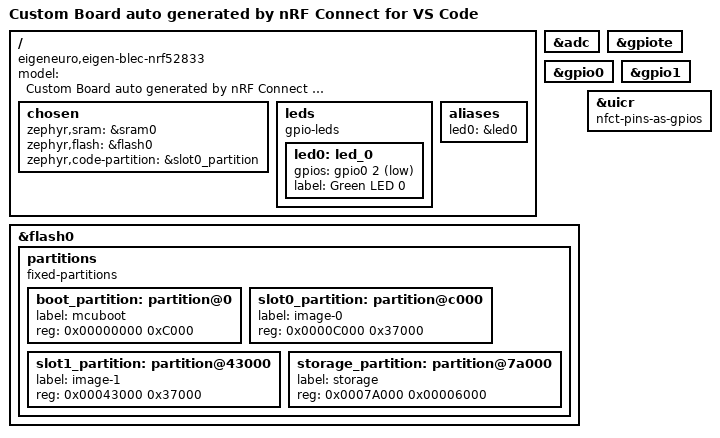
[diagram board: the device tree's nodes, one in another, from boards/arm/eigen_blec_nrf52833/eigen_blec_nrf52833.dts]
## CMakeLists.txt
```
cmake_minimum_required(VERSION 3.20.0)

list(APPEND BOARD_ROOT ${CMAKE_CURRENT_LIST_DIR})

find_package(Zephyr REQUIRED HINTS $ENV{ZEPHYR_BASE})
project(EigenBLEC)

FILE(GLOB app_sources src/*.c src/inc/*.h drivers/*.c drivers/*.h)
target_sources(app PRIVATE ${app_sources} src/main.c)

# Relax warnings-as-errors for unused variables in app sources.
target_compile_options(app PRIVATE -Wno-error=unused-variable)

# ---- Hard guard (file-based): strip UICR after zephyr.hex exists ----
find_package(Python3 REQUIRED COMPONENTS Interpreter)

set(ZEPHYR_HEX      ${PROJECT_BINARY_DIR}/zephyr/zephyr.hex)
set(ZEPHYR_HEX_NOUICR ${PROJECT_BINARY_DIR}/zephyr/zephyr.hex.nouicr)
set(STRIP_SCRIPT    ${CMAKE_CURRENT_LIST_DIR}/scripts/strip_uicr_hex.py)

add_custom_command(
  OUTPUT ${ZEPHYR_HEX_NOUICR}
  COMMAND ${CMAKE_COMMAND} -E echo "Stripping UICR from ${ZEPHYR_HEX}"
  COMMAND ${Python3_EXECUTABLE} ${STRIP_SCRIPT} ${ZEPHYR_HEX} ${ZEPHYR_HEX_NOUICR}
  COMMAND ${CMAKE_COMMAND} -E copy ${ZEPHYR_HEX_NOUICR} ${ZEPHYR_HEX}
  DEPENDS ${ZEPHYR_HEX} ${STRIP_SCRIPT}
  VERBATIM
)

add_custom_target(strip_uicr ALL DEPENDS ${ZEPHYR_HEX_NOUICR})

# Ensure west flash (ninja flash) runs strip_uicr first
if(TARGET flash)
  add_dependencies(flash strip_uicr)
endif()

# Some Zephyr versions use runners/flash targets with different names
if(TARGET runners)
  add_dependencies(runners strip_uicr)
endif()
```

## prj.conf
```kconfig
# 先把所有日志/控制台关掉（很多卡死发生在串口/console init）
CONFIG_LOG=y
CONFIG_CONSOLE=n
CONFIG_UART_CONSOLE=n
CONFIG_PRINTK=y
CONFIG_SERIAL=n
CONFIG_USE_SEGGER_RTT=y
CONFIG_SHELL_BACKEND_RTT=y

# printk/printf 支持 float
CONFIG_CBPRINTF_NANO=n
CONFIG_CBPRINTF_FP_SUPPORT=y

# 先关 flash/存储/文件系统（如果你工程里带了）
CONFIG_FLASH=y
CONFIG_FLASH_MAP=y
CONFIG_FLASH_PAGE_LAYOUT=y
CONFIG_SOC_FLASH_NRF=y
CONFIG_NVS=y
CONFIG_SETTINGS=n
CONFIG_FCB=n
CONFIG_FILE_SYSTEM=n

# 先别让任何低频时钟/外设复杂初始化影响（RC 32k，稳定）
CONFIG_CLOCK_CONTROL=y
CONFIG_CLOCK_CONTROL_NRF=y
CONFIG_CLOCK_CONTROL_NRF_K32SRC_RC=y
CONFIG_CLOCK_CONTROL_NRF_K32SRC_XTAL=n
CONFIG_CLOCK_CONTROL_NRF_K32SRC_SYNTH=n

###########################################################

################################
# Bluetooth Core
################################
CONFIG_BT=y
CONFIG_BT_PERIPHERAL=y
CONFIG_BT_DEVICE_NAME="BTrainer"

################################
# GATT / 需要 MTU 交换
################################
CONFIG_BT_GATT_CLIENT=y

################################
# PHY / DLE
################################
CONFIG_BT_CTLR_PHY_2M=y
CONFIG_BT_USER_PHY_UPDATE=y

CONFIG_BT_USER_DATA_LEN_UPDATE=y
CONFIG_BT_CTLR_DATA_LENGTH_MAX=251

################################
# MTU = 500（关键）
################################
CONFIG_BT_L2CAP_TX_MTU=500


# ATT MTU 交换：两边都至少 503（ATT=MTU，L2CAP/SDU 还要开销）
# Zephyr 的 ATT MTU 由 L2CAP_TX_MTU 驱动，但 buffer 也必须够
CONFIG_BT_BUF_ACL_TX_SIZE=500
CONFIG_BT_BUF_ACL_RX_SIZE=500

# 为了稳定，建议把 TX buffer 数量略抬高（默认有时不够导致 -ENOMEM）
CONFIG_BT_BUF_ACL_TX_COUNT=10
CONFIG_BT_BUF_EVT_RX_COUNT=12

################################
# Services
################################
CONFIG_BT_BAS=y
CONFIG_BT_DIS=y


################################
# DIS 信息（不走 settings）
################################
CONFIG_BT_DIS_PNP=n
CONFIG_BT_DIS_MODEL="EigenNeuroDev"
CONFIG_BT_DIS_MANUF="EigenNeuro"

CONFIG_BT_DIS_SERIAL_NUMBER=y
CONFIG_BT_DIS_SERIAL_NUMBER_STR="F.A000001"

CONFIG_BT_DIS_FW_REV=y
CONFIG_BT_DIS_FW_REV_STR="EigenNeuro Firmware"
CONFIG_BT_DIS_HW_REV=y
CONFIG_BT_DIS_HW_REV_STR="EigenNeuro Hardware"
CONFIG_BT_DIS_SW_REV=y
CONFIG_BT_DIS_SW_REV_STR="EigenNeuro Software"

CONFIG_BT_DIS_STR_MAX=32

################################
# ❌ 明确关闭 settings（否则必炸）
################################
CONFIG_BT_SETTINGS=n
CONFIG_SETTINGS=n
CONFIG_BT_DIS_SETTINGS=n


################################
# CONFIG
################################

CONFIG_GPIO=y
CONFIG_SPI=y
CONFIG_NRFX_SPIM=y

CONFIG_NRFX_TIMER=y

# CONFIG_NRFX_GPIOTE=y
CONFIG_PINCTRL=y
# CONFIG_I2C=y
CONFIG_ADC=y
CONFIG_NRFX_SAADC=y
CONFIG_REBOOT=y

# # OTA (MCUboot + MCUmgr over BLE SMP)
# CONFIG_BOOTLOADER_MCUBOOT=y
# CONFIG_ZCBOR=y
# CONFIG_MCUMGR=y
# CONFIG_MCUMGR_TRANSPORT_BT=y
# CONFIG_MCUMGR_GRP_IMG=y
# CONFIG_MCUMGR_GRP_OS=y
# CONFIG_IMG_MANAGER=y
# CONFIG_STREAM_FLASH=y

# # SMP service is registered dynamically in GATT
# CONFIG_BT_GATT_DYNAMIC_DB=y
```

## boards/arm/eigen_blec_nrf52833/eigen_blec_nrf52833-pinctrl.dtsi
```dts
&pinctrl {
};
```

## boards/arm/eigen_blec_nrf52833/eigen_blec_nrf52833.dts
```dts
/dts-v1/;
#include <nordic/nrf52833_qdaa.dtsi>
#include "eigen_blec_nrf52833-pinctrl.dtsi"

/ {
	model = "Custom Board auto generated by nRF Connect for VS Code";
	compatible = "eigeneuro,eigen-blec-nrf52833";

	chosen {
		zephyr,sram = &sram0;
		zephyr,flash = &flash0;
		zephyr,code-partition = &slot0_partition;
	};

	leds {
		compatible = "gpio-leds";

		led0: led_0 {
			gpios = <&gpio0 2 GPIO_ACTIVE_LOW>;
			label = "Green LED 0";
		};
  };

  aliases {
      led0 = &led0;
  };
};

&adc {
	status = "okay";
};

&gpiote {
	status = "okay";
};

&gpio0 {
	status = "okay";
};

&gpio1 {
	status = "okay";
};

&flash0 {
  status = "okay";

	partitions {
		compatible = "fixed-partitions";
		#address-cells = <1>;
		#size-cells = <1>;

		boot_partition: partition@0 {
			label = "mcuboot";
			reg = <0x00000000 0xC000>;
		};

		slot0_partition: partition@c000 {
			label = "image-0";
			reg = <0x0000C000 0x37000>;
		};

		slot1_partition: partition@43000 {
			label = "image-1";
			reg = <0x00043000 0x37000>;
		};

		storage_partition: partition@7a000 {
			label = "storage";
			reg = <0x0007A000 0x00006000>;
		};
	};
};

&uicr {
	/* 将 NFC 引脚复用为 GPIO（P0.09/P0.10） */
	nfct-pins-as-gpios;
};
```

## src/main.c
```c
#include <zephyr/kernel.h>

#include "inc/ble.h"
#include "inc/task_imu.h"
#include "inc/pba.h"
#include "inc/persistence.h"

int event_after_startup()
{
  presistence_init();
  ble_init();
  task_imu_init();
  task_imu_start();
  return 0;
}
int event_before_shutdown()
{
  //// do nothing.
  // task_imu_stop();
  // task_imu_uninit();
  // ble_uninit();
  return 0;
}


int main(void)
{
  // 初始化
  pba_init();


  k_msleep(4000); // 开机后的 5s 内不允许按钮逻辑，否则容易重复触发开关机操作

  for(;;) {
    k_msleep(1);
    pba_loop();
    static uint32_t count = 0;
    if (count++ % 1000 == 0) {
      printk("live! [%d]\n", count);
    }
  }
  return 0;
}
```

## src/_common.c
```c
#include "inc/_common.h"

static bool stub = false;
bool hard_stub() {
  return stub;
}

bool hard_lock() {
  stub = true;
  return true;
}

bool hard_unlock() {
  stub = false;
  return true;
}
```

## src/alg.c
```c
#include "inc/alg.h"

#include <errno.h>
#include <math.h>
#include <stdbool.h>
#include <string.h>

#ifndef M_PI
#define M_PI 3.14159265358979323846
#endif

static volatile alg_config_t config;

typedef struct {
  float q0;
  float q1;
  float q2;
  float q3;
  float integral_fb_x;
  float integral_fb_y;
  float integral_fb_z;
  float ax_f;
  float ay_f;
  float az_f;
  float gx_f;
  float gy_f;
  float gz_f;
  float mx_f;
  float my_f;
  float mz_f;
  bool filter_valid;
  float abx;
  float aby;
  float abz;
  world_pos_t current;
  bool valid;
} alg_state_t;

static alg_state_t state = {
  .q0 = 1.0f,
  .q1 = 0.0f,
  .q2 = 0.0f,
  .q3 = 0.0f,
};

static inline bool is_finite3(float x, float y, float z)
{
  return isfinite(x) && isfinite(y) && isfinite(z);
}

static inline float inv_sqrt(float x)
{
  if (x <= 0.0f || !isfinite(x)) {
    return 0.0f;
  }
  return 1.0f / sqrtf(x);
}

static inline float norm3(float x, float y, float z)
{
  return sqrtf(x * x + y * y + z * z);
}

static inline float lpf_update(float prev, float input, float alpha)
{
  return prev + alpha * (input - prev);
}

static inline float angle_diff_deg(float a, float b)
{
  float d = a - b;
  while (d > 180.0f) {
    d -= 360.0f;
  }
  while (d < -180.0f) {
    d += 360.0f;
  }
  return d;
}

static inline void gravity_body_from_quat(const alg_state_t *st, float *gx, float *gy, float *gz)
{
  float q0 = st->q0;
  float q1 = st->q1;
  float q2 = st->q2;
  float q3 = st->q3;
  *gx = 2.0f * (q1 * q3 - q0 * q2);
  *gy = 2.0f * (q0 * q1 + q2 * q3);
  *gz = q0 * q0 - q1 * q1 - q2 * q2 + q3 * q3;
}

static inline bool normalize3(float *x, float *y, float *z)
{
  float n2 = (*x) * (*x) + (*y) * (*y) + (*z) * (*z);
  float inv = inv_sqrt(n2);
  if (inv <= 0.0f) {
    return false;
  }
  *x *= inv;
  *y *= inv;
  *z *= inv;
  return true;
}

static inline void quat_normalize(alg_state_t *st)
{
  float inv = inv_sqrt(st->q0 * st->q0 + st->q1 * st->q1 + st->q2 * st->q2 + st->q3 * st->q3);
  if (inv <= 0.0f) {
    st->q0 = 1.0f;
    st->q1 = st->q2 = st->q3 = 0.0f;
    return;
  }
  st->q0 *= inv;
  st->q1 *= inv;
  st->q2 *= inv;
  st->q3 *= inv;
}

static inline void quat_to_euler(const alg_state_t *st, float *yaw, float *pitch, float *roll)
{
  float q0 = st->q0;
  float q1 = st->q1;
  float q2 = st->q2;
  float q3 = st->q3;

  float sinr_cosp = 2.0f * (q0 * q1 + q2 * q3);
  float cosr_cosp = 1.0f - 2.0f * (q1 * q1 + q2 * q2);
  float r = atan2f(sinr_cosp, cosr_cosp);

  float sinp = 2.0f * (q0 * q2 - q3 * q1);
  float p;
  if (fabsf(sinp) >= 1.0f) {
    p = copysignf((float)M_PI / 2.0f, sinp);
  } else {
    p = asinf(sinp);
  }

  float siny_cosp = 2.0f * (q0 * q3 + q1 * q2);
  float cosy_cosp = 1.0f - 2.0f * (q2 * q2 + q3 * q3);
  float y = atan2f(siny_cosp, cosy_cosp);

  // 输出单位：deg
  const float rad2deg = 57.2957795f;
  *yaw = y * rad2deg;
  *pitch = p * rad2deg;
  *roll = r * rad2deg;
}

static inline void rotate_body_to_world(const alg_state_t *st, float bx, float by, float bz,
                                        float *wx, float *wy, float *wz)
{
  float q0 = st->q0;
  float q1 = st->q1;
  float q2 = st->q2;
  float q3 = st->q3;

  *wx = (1.0f - 2.0f * (q2 * q2 + q3 * q3)) * bx +
        2.0f * (q1 * q2 - q0 * q3) * by +
        2.0f * (q1 * q3 + q0 * q2) * bz;
  *wy = 2.0f * (q1 * q2 + q0 * q3) * bx +
        (1.0f - 2.0f * (q1 * q1 + q3 * q3)) * by +
        2.0f * (q2 * q3 - q0 * q1) * bz;
  *wz = 2.0f * (q1 * q3 - q0 * q2) * bx +
        2.0f * (q2 * q3 + q0 * q1) * by +
        (1.0f - 2.0f * (q1 * q1 + q2 * q2)) * bz;
}

static void mahony_update(alg_state_t *st,
                          float gx, float gy, float gz,
                          float ax, float ay, float az,
                          float mx, float my, float mz,
                          float dt)
{
  // 参数：建议根据噪声/采样率再调优
  const float kp = 2.0f;
  const float ki = 0.01f;

  if (!is_finite3(ax, ay, az) || !is_finite3(gx, gy, gz)) {
    return;
  }

  bool acc_ok = normalize3(&ax, &ay, &az);
  if (!acc_ok) {
    return;
  }

  bool mag_ok = is_finite3(mx, my, mz) && normalize3(&mx, &my, &mz);

  // Estimated gravity direction
  float q0 = st->q0;
  float q1 = st->q1;
  float q2 = st->q2;
  float q3 = st->q3;

  float vx = 2.0f * (q1 * q3 - q0 * q2);
  float vy = 2.0f * (q0 * q1 + q2 * q3);
  float vz = q0 * q0 - q1 * q1 - q2 * q2 + q3 * q3;

  float ex = 0.0f;
  float ey = 0.0f;
  float ez = 0.0f;

  if (mag_ok) {
    // Reference direction of Earth's magnetic field
    float hx = 2.0f * mx * (0.5f - q2 * q2 - q3 * q3) +
               2.0f * my * (q1 * q2 - q0 * q3) +
               2.0f * mz * (q1 * q3 + q0 * q2);
    float hy = 2.0f * mx * (q1 * q2 + q0 * q3) +
               2.0f * my * (0.5f - q1 * q1 - q3 * q3) +
               2.0f * mz * (q2 * q3 - q0 * q1);
    float bx = sqrtf(hx * hx + hy * hy);
    float bz = 2.0f * mx * (q1 * q3 - q0 * q2) +
               2.0f * my * (q2 * q3 + q0 * q1) +
               2.0f * mz * (0.5f - q1 * q1 - q2 * q2);

    // Estimated direction of magnetic field
    float wx = 2.0f * bx * (0.5f - q2 * q2 - q3 * q3) +
               2.0f * bz * (q1 * q3 - q0 * q2);
    float wy = 2.0f * bx * (q1 * q2 - q0 * q3) +
               2.0f * bz * (q0 * q1 + q2 * q3);
    float wz = 2.0f * bx * (q0 * q2 + q1 * q3) +
               2.0f * bz * (0.5f - q1 * q1 - q2 * q2);

    ex = (ay * vz - az * vy) + (my * wz - mz * wy);
    ey = (az * vx - ax * vz) + (mz * wx - mx * wz);
    ez = (ax * vy - ay * vx) + (mx * wy - my * wx);
  } else {
    ex = (ay * vz - az * vy);
    ey = (az * vx - ax * vz);
    ez = (ax * vy - ay * vx);
  }

  if (ki > 0.0f && isfinite(dt) && dt > 0.0f) {
    st->integral_fb_x += ki * ex * dt;
    st->integral_fb_y += ki * ey * dt;
    st->integral_fb_z += ki * ez * dt;
  } else {
    st->integral_fb_x = 0.0f;
    st->integral_fb_y = 0.0f;
    st->integral_fb_z = 0.0f;
  }

  gx += kp * ex + st->integral_fb_x;
  gy += kp * ey + st->integral_fb_y;
  gz += kp * ez + st->integral_fb_z;

  // Integrate quaternion rate and normalize
  float half_dt = 0.5f * dt;
  float qa = q0;
  float qb = q1;
  float qc = q2;

  q0 += (-qb * gx - qc * gy - q3 * gz) * half_dt;
  q1 += (qa * gx + qc * gz - q3 * gy) * half_dt;
  q2 += (qa * gy - qb * gz + q3 * gx) * half_dt;
  q3 += (qa * gz + qb * gy - qc * gx) * half_dt;

  st->q0 = q0;
  st->q1 = q1;
  st->q2 = q2;
  st->q3 = q3;
  quat_normalize(st);
}

int alg_imu_init(alg_config_t cfg)
{
  if (cfg.sample_us == 0) {
    cfg.sample_us = 2000; // 默认 500Hz
  }
  config = cfg;

  memset(&state, 0, sizeof(state));
  state.q0 = 1.0f;
  state.valid = false;
  return 0;
}

/**
 * 以固定频率采集并更新至此
 */
int alg_imu_update(imu_data_t * data)
{
  if (!data) {
    return -EINVAL;
  }

  float ax = data->ax;
  float ay = data->ay;
  float az = data->az;
  float gx = data->gx;
  float gy = data->gy;
  float gz = data->gz;
  float mx = data->mx;
  float my = data->my;
  float mz = data->mz;

  float dt = (float)config.sample_us / 1000000.0f;
  if (!isfinite(dt) || dt <= 0.0f) {
    dt = 0.002f;
  }

  // 简单一阶低通，抑制高频抖动噪声
  // 截止频率可按实际噪声/响应再调整
  const float acc_cutoff_hz = 10.0f;
  const float gyro_cutoff_hz = 20.0f;
  const float mag_cutoff_hz = 10.0f;
  const float tau_acc = 1.0f / (2.0f * (float)M_PI * acc_cutoff_hz);
  const float tau_gyro = 1.0f / (2.0f * (float)M_PI * gyro_cutoff_hz);
  const float tau_mag = 1.0f / (2.0f * (float)M_PI * mag_cutoff_hz);
  const float alpha_acc = dt / (tau_acc + dt);
  const float alpha_gyro = dt / (tau_gyro + dt);
  const float alpha_mag = dt / (tau_mag + dt);

  if (!state.filter_valid) {
    state.ax_f = ax;
    state.ay_f = ay;
    state.az_f = az;
    state.gx_f = gx;
    state.gy_f = gy;
    state.gz_f = gz;
    state.mx_f = mx;
    state.my_f = my;
    state.mz_f = mz;
    state.filter_valid = true;
  } else {
    if (is_finite3(ax, ay, az)) {
      state.ax_f = lpf_update(state.ax_f, ax, alpha_acc);
      state.ay_f = lpf_update(state.ay_f, ay, alpha_acc);
      state.az_f = lpf_update(state.az_f, az, alpha_acc);
    }
    if (is_finite3(gx, gy, gz)) {
      state.gx_f = lpf_update(state.gx_f, gx, alpha_gyro);
      state.gy_f = lpf_update(state.gy_f, gy, alpha_gyro);
      state.gz_f = lpf_update(state.gz_f, gz, alpha_gyro);
    }
    if (is_finite3(mx, my, mz)) {
      state.mx_f = lpf_update(state.mx_f, mx, alpha_mag);
      state.my_f = lpf_update(state.my_f, my, alpha_mag);
      state.mz_f = lpf_update(state.mz_f, mz, alpha_mag);
    }
  }

  ax = state.ax_f;
  ay = state.ay_f;
  az = state.az_f;
  gx = state.gx_f;
  gy = state.gy_f;
  gz = state.gz_f;
  mx = state.mx_f;
  my = state.my_f;
  mz = state.mz_f;

  // 角速度幅值（dps），用于静止检测
  float gyro_norm_dps = norm3(gx, gy, gz);

  // 输入单位假设：加速度 mg，角速度 dps（来自驱动配置）
  const float deg2rad = 0.01745329252f;
  gx *= deg2rad;
  gy *= deg2rad;
  gz *= deg2rad;

  mahony_update(&state, gx, gy, gz, ax, ay, az, mx, my, mz, dt);

  // 线加速度（m/s^2），机体坐标系，去除重力分量
  const float g_ref_mg = 1000.0f;
  const float mg_to_mps2 = 0.00980665f;
  float gbx, gby, gbz;
  gravity_body_from_quat(&state, &gbx, &gby, &gbz);
  float lin_bx_mg = ax - gbx * g_ref_mg;
  float lin_by_mg = ay - gby * g_ref_mg;
  float lin_bz_mg = az - gbz * g_ref_mg;
  float lin_bx = lin_bx_mg * mg_to_mps2;
  float lin_by = lin_by_mg * mg_to_mps2;
  float lin_bz = lin_bz_mg * mg_to_mps2;

  // 简单零偏估计：静止时用低通估计线加速度偏置
  const float gyro_stationary_dps = 1.5f;
  const float lin_acc_stationary = 0.2f; // m/s^2
  const float acc_norm_stationary_mg = 50.0f;
  float acc_norm_mg = norm3(ax, ay, az);
  bool stationary = (gyro_norm_dps < gyro_stationary_dps) &&
                    (fabsf(acc_norm_mg - g_ref_mg) < acc_norm_stationary_mg) &&
                    (norm3(lin_bx, lin_by, lin_bz) < lin_acc_stationary);

  if (stationary && is_finite3(lin_bx, lin_by, lin_bz)) {
    const float bias_alpha = 0.01f;
    state.abx = lpf_update(state.abx, lin_bx, bias_alpha);
    state.aby = lpf_update(state.aby, lin_by, bias_alpha);
    state.abz = lpf_update(state.abz, lin_bz, bias_alpha);
  }

  // 去除估计偏置
  lin_bx -= state.abx;
  lin_by -= state.aby;
  lin_bz -= state.abz;

  state.current.ax = lin_bx;
  state.current.ay = lin_by;
  state.current.az = lin_bz;

  quat_to_euler(&state, &state.current.yaw, &state.current.pitch, &state.current.roll);
  state.valid = true;

  // if return 0, call: #alg_imu_get_current/1
  return 0;
}

/**
 * 获取解算出来的最新姿势（世界坐标）
 */
int alg_imu_get_current(world_pos_t * position)
{
  if (!position) {
    return -EINVAL;
  }
  if (!state.valid) {
    return -EAGAIN;
  }
  *position = state.current;
  return 0;
}

bool alg_imu_is_yaw_balanced(void)
{
  if (!state.valid) {
    return false;
  }
  if (config.balance_yaw_thresh < 0.0f) {
    return true;
  }
  float dy = angle_diff_deg(state.current.yaw, config.balance_yaw);
  return fabsf(dy) <= config.balance_yaw_thresh;
}

bool alg_imu_is_pitch_balanced(void)
{
  if (!state.valid) {
    return false;
  }
  if (config.balance_pitch_thresh < 0.0f) {
    return true;
  }
  float dp = angle_diff_deg(state.current.pitch, config.balance_pitch);
  return fabsf(dp) <= config.balance_pitch_thresh;
}

bool alg_imu_is_roll_balanced(void)
{
  if (!state.valid) {
    return false;
  }
  if (config.balance_roll_thresh < 0.0f) {
    return true;
  }
  float dr = angle_diff_deg(state.current.roll, config.balance_roll);
  return fabsf(dr) <= config.balance_roll_thresh;
}

int alg_update_threshold(uint8_t axis, float threshold_deg)
{
  switch (axis) {
    case ALG_AXIS_YAW:
      config.balance_yaw_thresh = threshold_deg;
      break;
    case ALG_AXIS_PITCH:
      config.balance_pitch_thresh = threshold_deg;
      break;
    case ALG_AXIS_ROLL:
      config.balance_roll_thresh = threshold_deg;
      break;
    default:
      return -EINVAL;
  }

  return 0;
}
```

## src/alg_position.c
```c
#include "inc/alg_position.h"

#include <math.h>
#include <stdbool.h>

#ifndef M_PI
#define M_PI 3.14159265358979323846
#endif

typedef struct {
  float x;
  float y;
  float z;
  float vx;
  float vy;
  float vz;
  float bx;
  float by;
  float bz;
  float g_ref_mg;
  world_posture_t last;
  bool valid;
} pos_state_t;

static pos_state_t state = {
  // 使用 mg 作为加速度输入单位：1 g = 1000 mg
  .g_ref_mg = 1000.0f,
};

static inline float lpf_update(float prev, float input, float alpha)
{
  return prev + alpha * (input - prev);
}

static inline float angle_diff_deg(float a, float b)
{
  float d = a - b;
  while (d > 180.0f) {
    d -= 360.0f;
  }
  while (d < -180.0f) {
    d += 360.0f;
  }
  return d;
}

static inline float norm3(float x, float y, float z)
{
  return sqrtf(x * x + y * y + z * z);
}

static inline void rotate_body_to_world_euler(float bx, float by, float bz,
                                              float yaw_deg, float pitch_deg, float roll_deg,
                                              float *wx, float *wy, float *wz)
{
  const float deg2rad = (float)M_PI / 180.0f;
  float yaw = yaw_deg * deg2rad;
  float pitch = pitch_deg * deg2rad;
  float roll = roll_deg * deg2rad;

  float cy = cosf(yaw);
  float sy = sinf(yaw);
  float cp = cosf(pitch);
  float sp = sinf(pitch);
  float cr = cosf(roll);
  float sr = sinf(roll);

  float r11 = cy * cp;
  float r12 = cy * sp * sr - sy * cr;
  float r13 = cy * sp * cr + sy * sr;
  float r21 = sy * cp;
  float r22 = sy * sp * sr + cy * cr;
  float r23 = sy * sp * cr - cy * sr;
  float r31 = -sp;
  float r32 = cp * sr;
  float r33 = cp * cr;

  *wx = r11 * bx + r12 * by + r13 * bz;
  *wy = r21 * bx + r22 * by + r23 * bz;
  *wz = r31 * bx + r32 * by + r33 * bz;
}

world_position_t alg_position_update(const world_posture_t *posture,
                                     const imu_data_t *imu)
{
  if (!posture || !imu) {
    world_position_t empty = {
      .x = state.x,
      .y = state.y,
      .z = state.z,
      .yaw = state.last.yaw,
      .pitch = state.last.pitch,
      .roll = state.last.roll,
    };
    return empty;
  }

  world_posture_t posture_val = *posture;
  // 位置解算流程（基于原始加速度）：
  // 1) 使用姿态角（yaw/pitch/roll）将“原始 IMU 加速度”从机体坐标系旋转到世界坐标系
  // 2) 在世界坐标系去掉重力分量，得到线加速度
  // 3) 静止检测时估计偏置并清零速度，抑制积分漂移
  // 4) 积分得到速度与位置（只作为短时间相对位移参考）
  //
  // 重要：加速度输入单位为 mg（1 g = 1000 mg）。
  // 这里先在 mg 单位下做旋转和去重力，再统一换算到 m/s^2。

  world_position_t out = {
    .x = state.x,
    .y = state.y,
    .z = state.z,
    .yaw = posture_val.yaw,
    .pitch = posture_val.pitch,
    .roll = posture_val.roll,
  };

  if (!state.valid) {
    state.last = posture_val;
    state.valid = true;
    return out;
  }

  float dt = (float)ALG_POSITION_SAMPLE_US / 1000000.0f;
  if (!isfinite(dt) || dt <= 0.0f) {
    dt = 0.01f;
  }

  // 原始 IMU 加速度（mg）
  float ax_mg = imu->ax;
  float ay_mg = imu->ay;
  float az_mg = imu->az;

  if (!isfinite(ax_mg) || !isfinite(ay_mg) || !isfinite(az_mg)) {
    return out;
  }

  // 将机体系“原始加速度（mg）”旋转到世界坐标系
  float wx_mg, wy_mg, wz_mg;
  rotate_body_to_world_euler(ax_mg, ay_mg, az_mg,
                             posture_val.yaw, posture_val.pitch, posture_val.roll,
                             &wx_mg, &wy_mg, &wz_mg);

  // 世界系重力向量约为 (0, 0, +1g)；从原始加速度中去除
  float lin_wx_mg = wx_mg;
  float lin_wy_mg = wy_mg;
  float lin_wz_mg = wz_mg - state.g_ref_mg;

  // 统一换算到 m/s^2，避免后续阈值与积分混乱
  const float mg_to_mps2 = 0.00980665f;
  float lin_wx = lin_wx_mg * mg_to_mps2;
  float lin_wy = lin_wy_mg * mg_to_mps2;
  float lin_wz = lin_wz_mg * mg_to_mps2;

  float dy = angle_diff_deg(posture_val.yaw, state.last.yaw);
  float dp = angle_diff_deg(posture_val.pitch, state.last.pitch);
  float dr = angle_diff_deg(posture_val.roll, state.last.roll);
  float max_d = fmaxf(fmaxf(fabsf(dy), fabsf(dp)), fabsf(dr));
  float lin_norm = norm3(lin_wx, lin_wy, lin_wz);

  // 静止检测：角度变化小 + 线加速度小
  const float stationary_angle_deg = 1.0f;
  const float stationary_lin_mps2 = 0.2f;
  bool stationary = (max_d < stationary_angle_deg) && (lin_norm < stationary_lin_mps2);

  if (stationary) {
    // 静止时低通估计偏置，抑制积分漂移
    const float bias_alpha = 0.02f;
    state.bx = lpf_update(state.bx, lin_wx, bias_alpha);
    state.by = lpf_update(state.by, lin_wy, bias_alpha);
    state.bz = lpf_update(state.bz, lin_wz, bias_alpha);
    state.vx = 0.0f;
    state.vy = 0.0f;
    state.vz = 0.0f;

    // 静止时轻微修正 g 参考值（单位 mg），用于抵消量程误差
    float acc_norm_mg = norm3(ax_mg, ay_mg, az_mg);
    if (isfinite(acc_norm_mg)) {
      const float g_alpha = 0.01f;
      state.g_ref_mg = lpf_update(state.g_ref_mg, acc_norm_mg, g_alpha);
    }
  }

  // 去除静止偏置后再积分
  lin_wx -= state.bx;
  lin_wy -= state.by;
  lin_wz -= state.bz;

  // 速度积分
  state.vx += lin_wx * dt;
  state.vy += lin_wy * dt;
  state.vz += lin_wz * dt;

  // 位置积分
  state.x += state.vx * dt;
  state.y += state.vy * dt;
  state.z += state.vz * dt;

  state.last = posture_val;

  out.x = state.x;
  out.y = state.y;
  out.z = state.z;
  return out;
}
```

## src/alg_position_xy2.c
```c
// #define ENABLE_IT
#ifdef ENABLE_IT

#include "inc/alg_posture.h"
#include "inc/alg_position.h"

#include <errno.h>
#include <math.h>
#include <stdbool.h>
#include <string.h>

#ifndef M_PI
#define M_PI 3.14159265358979323846
#endif

// ------------------------------------------------------------
// Notes / Assumptions (matches your previous implementation):
// - imu_data_t:
//     accel: mg (1 g = 1000 mg)
//     gyro : dps (deg/s)
//     mag  : any linear unit (uT or raw), only direction is used (normalized)
// - Output world_posture_t:
//     yaw/pitch/roll: degrees
//     ax/ay/az: linear acceleration in BODY frame, unit m/s^2 (gravity removed + bias compensated)
// - Position integration (alg_position_update):
//     uses original accel (mg) + current quaternion to rotate to world,
//     integrates to get short-term relative displacement (meters).
// ------------------------------------------------------------

// posture config is provided by inc/alg_posture.h (kept identical API)
static volatile alg_posture_config_t posture_config;

// ------------------------ internal state ------------------------
typedef struct {
  // quaternion (world<-body) as used in Mahony (unit)
  float q0, q1, q2, q3;

  // integral feedback for Mahony
  float integral_fb_x;
  float integral_fb_y;
  float integral_fb_z;

  // filtered sensor values (same unit as input)
  float ax_f, ay_f, az_f;
  float gx_f, gy_f, gz_f;
  float mx_f, my_f, mz_f;
  bool filter_valid;

  // estimated gravity direction in BODY (unit vector), derived from quaternion
  float gbx, gby, gbz;

  // linear accel bias estimate in BODY (m/s^2), adapted when stationary
  float abx, aby, abz;

  // output cache
  world_posture_t current;
  bool valid;
} posture_state_t;

static posture_state_t state = {
  .q0 = 1.0f,
};

// position state (used by alg_position_update)
typedef struct {
  float x, y, z;       // m
  float vx, vy, vz;    // m/s

  // World-frame linear-acc bias estimate (m/s^2). This is a *slow* LPF of a_lin_world.
  // It is updated always, and faster when stationary, to suppress DC drift that otherwise
  // integrates into a straight-line runaway.
  float bx, by, bz;

  // World-frame linear-acc filtered (m/s^2) used for integration (after bias removal).
  float ax_f, ay_f, az_f;

  // gravity magnitude reference in mg (normally ~1000)
  float g_ref_mg;

  world_posture_t last;
  bool valid;
} position_state_t;

static position_state_t pos_state = {
  .g_ref_mg = 1000.0f,
};

// ------------------------ small helpers ------------------------
static inline bool is_finite3(float x, float y, float z)
{
  return isfinite(x) && isfinite(y) && isfinite(z);
}

static inline float lpf_update(float prev, float input, float alpha)
{
  return prev + alpha * (input - prev);
}

static inline float inv_sqrtf(float x)
{
  // safe inverse sqrt
  if (!isfinite(x) || x <= 0.0f) {
    return 0.0f;
  }
  return 1.0f / sqrtf(x);
}

static inline float norm3(float x, float y, float z)
{
  return sqrtf(x * x + y * y + z * z);
}

static inline float angle_diff_deg(float a, float b)
{
  float d = a - b;
  while (d > 180.0f) {
    d -= 360.0f;
  }
  while (d < -180.0f) {
    d += 360.0f;
  }
  return d;
}

// quaternion normalization
static inline void quat_normalize(posture_state_t *s)
{
  float n = s->q0 * s->q0 + s->q1 * s->q1 + s->q2 * s->q2 + s->q3 * s->q3;
  float inv = inv_sqrtf(n);
  if (inv > 0.0f) {
    s->q0 *= inv;
    s->q1 *= inv;
    s->q2 *= inv;
    s->q3 *= inv;
  } else {
    // fallback to identity if broken
    s->q0 = 1.0f;
    s->q1 = s->q2 = s->q3 = 0.0f;
  }
}

// gravity direction in BODY from quaternion (unit vector)
// matches typical AHRS derivation (assuming world Z is "up")
static inline void gravity_body_from_quat(posture_state_t *s, float *gbx, float *gby, float *gbz)
{
  // Using quaternion (q0,q1,q2,q3) where q rotates body -> world.
  // Gravity direction in body is third column of Rwb (world->body) applied to world Z.
  // Derived commonly as:
  // gbx = 2*(q1*q3 - q0*q2)
  // gby = 2*(q0*q1 + q2*q3)
  // gbz = q0^2 - q1^2 - q2^2 + q3^2
  float q0 = s->q0, q1 = s->q1, q2 = s->q2, q3 = s->q3;
  float x = 2.0f * (q1 * q3 - q0 * q2);
  float y = 2.0f * (q0 * q1 + q2 * q3);
  float z = q0 * q0 - q1 * q1 - q2 * q2 + q3 * q3;

  // normalize for safety
  float inv = inv_sqrtf(x * x + y * y + z * z);
  if (inv > 0.0f) {
    x *= inv;
    y *= inv;
    z *= inv;
  }
  *gbx = x;
  *gby = y;
  *gbz = z;
}

// Body->World rotation for a BODY vector using quaternion
static inline void rotate_body_to_world(const posture_state_t *s,
                                        float bx, float by, float bz,
                                        float *wx, float *wy, float *wz)
{
  // v_w = q * v_b * q_conj
  float q0 = s->q0, q1 = s->q1, q2 = s->q2, q3 = s->q3;

  // t = 2 * cross(q_vec, v)
  float tx = 2.0f * (q2 * bz - q3 * by);
  float ty = 2.0f * (q3 * bx - q1 * bz);
  float tz = 2.0f * (q1 * by - q2 * bx);

  // v' = v + q0*t + cross(q_vec, t)
  float cx = q2 * tz - q3 * ty;
  float cy = q3 * tx - q1 * tz;
  float cz = q1 * ty - q2 * tx;

  *wx = bx + q0 * tx + cx;
  *wy = by + q0 * ty + cy;
  *wz = bz + q0 * tz + cz;
}

static inline void rotate_world_to_body(const posture_state_t *s,
                                        float wx, float wy, float wz,
                                        float *bx, float *by, float *bz)
{
  // inverse rotation (BODY<-WORLD) for unit quaternion: use conjugate
  // v_b = q_conj * v_w * q
  float q0 = s->q0, q1 = -s->q1, q2 = -s->q2, q3 = -s->q3;

  float tx = 2.0f * (q2 * wz - q3 * wy);
  float ty = 2.0f * (q3 * wx - q1 * wz);
  float tz = 2.0f * (q1 * wy - q2 * wx);

  float cx = q2 * tz - q3 * ty;
  float cy = q3 * tx - q1 * tz;
  float cz = q1 * ty - q2 * tx;

  *bx = wx + q0 * tx + cx;
  *by = wy + q0 * ty + cy;
  *bz = wz + q0 * tz + cz;
}

// Quaternion -> Euler (yaw, pitch, roll) in degrees
static inline void quat_to_euler_deg(const posture_state_t *s, float *yaw, float *pitch, float *roll)
{
  float q0 = s->q0, q1 = s->q1, q2 = s->q2, q3 = s->q3;

  // yaw (Z)
  float ys = 2.0f * (q0 * q3 + q1 * q2);
  float yc = 1.0f - 2.0f * (q2 * q2 + q3 * q3);
  float y = atan2f(ys, yc);

  // pitch (Y)
  float ps = 2.0f * (q0 * q2 - q3 * q1);
  ps = fminf(fmaxf(ps, -1.0f), 1.0f);
  float p = asinf(ps);

  // roll (X)
  float rs = 2.0f * (q0 * q1 + q2 * q3);
  float rc = 1.0f - 2.0f * (q1 * q1 + q2 * q2);
  float r = atan2f(rs, rc);

  const float rad2deg = 180.0f / (float)M_PI;
  *yaw = y * rad2deg;
  *pitch = p * rad2deg;
  *roll = r * rad2deg;
}

// ------------------------ Mahony AHRS ------------------------
// This implementation is intentionally conservative and stable for motion analysis:
// - always normalizes accel/mag (so scale doesn't matter)
// - integrates gyro (rad/s)
// - uses accel+mag correction when valid
static void mahony_update(posture_state_t *s,
                          float gx_rps, float gy_rps, float gz_rps,
                          float ax_mg, float ay_mg, float az_mg,
                          float mx, float my, float mz,
                          float dt)
{
  // gains (tune as you like)
  // larger Kp => faster correction but more noise
  const float Kp = 2.0f;
  const float Ki = 0.05f;

  // normalize accelerometer
  float ax = ax_mg, ay = ay_mg, az = az_mg;
  float an = ax * ax + ay * ay + az * az;
  float inv_an = inv_sqrtf(an);
  bool acc_ok = (inv_an > 0.0f);
  if (acc_ok) {
    ax *= inv_an;
    ay *= inv_an;
    az *= inv_an;
  }

  // normalize magnetometer (optional)
  float mxn = mx, myn = my, mzn = mz;
  float mn = mxn * mxn + myn * myn + mzn * mzn;
  float inv_mn = inv_sqrtf(mn);
  bool mag_ok = (inv_mn > 0.0f);
  if (mag_ok) {
    mxn *= inv_mn;
    myn *= inv_mn;
    mzn *= inv_mn;
  }

  float q0 = s->q0, q1 = s->q1, q2 = s->q2, q3 = s->q3;

  float ex = 0.0f, ey = 0.0f, ez = 0.0f;

  if (acc_ok) {
    // Estimated direction of gravity (from quaternion) in BODY coordinates
    // Same as gravity_body_from_quat, but we compute quickly here.
    float vx = 2.0f * (q1 * q3 - q0 * q2);
    float vy = 2.0f * (q0 * q1 + q2 * q3);
    float vz = q0 * q0 - q1 * q1 - q2 * q2 + q3 * q3;

    // Error is cross(acc_meas, gravity_est)
    ex += (ay * vz - az * vy);
    ey += (az * vx - ax * vz);
    ez += (ax * vy - ay * vx);
  }

  if (acc_ok && mag_ok) {
    // Reference direction of Earth's magnetic field
    float hx = 2.0f * (mxn * (0.5f - q2 * q2 - q3 * q3) +
                       myn * (q1 * q2 - q0 * q3) +
                       mzn * (q1 * q3 + q0 * q2));
    float hy = 2.0f * (mxn * (q1 * q2 + q0 * q3) +
                       myn * (0.5f - q1 * q1 - q3 * q3) +
                       mzn * (q2 * q3 - q0 * q1));
    float bx = sqrtf(hx * hx + hy * hy);
    float bz = 2.0f * (mxn * (q1 * q3 - q0 * q2) +
                       myn * (q2 * q3 + q0 * q1) +
                       mzn * (0.5f - q1 * q1 - q2 * q2));

    // Estimated direction of magnetic field
    float wx = 2.0f * (bx * (0.5f - q2 * q2 - q3 * q3) + bz * (q1 * q3 - q0 * q2));
    float wy = 2.0f * (bx * (q1 * q2 - q0 * q3) + bz * (q0 * q1 + q2 * q3));
    float wz = 2.0f * (bx * (q0 * q2 + q1 * q3) + bz * (0.5f - q1 * q1 - q2 * q2));

    // Error is cross(mag_meas, mag_est)
    ex += (myn * wz - mzn * wy);
    ey += (mzn * wx - mxn * wz);
    ez += (mxn * wy - myn * wx);
  }

  // Integral feedback
  if (Ki > 0.0f) {
    s->integral_fb_x += Ki * ex * dt;
    s->integral_fb_y += Ki * ey * dt;
    s->integral_fb_z += Ki * ez * dt;

    gx_rps += s->integral_fb_x;
    gy_rps += s->integral_fb_y;
    gz_rps += s->integral_fb_z;
  } else {
    s->integral_fb_x = 0.0f;
    s->integral_fb_y = 0.0f;
    s->integral_fb_z = 0.0f;
  }

  // Proportional feedback
  gx_rps += Kp * ex;
  gy_rps += Kp * ey;
  gz_rps += Kp * ez;

  // Integrate quaternion rate: q_dot = 0.5 * q ⊗ [0, gyro]
  float half_dt = 0.5f * dt;
  float qa = q0;
  float qb = q1;
  float qc = q2;
  float qd = q3;

  q0 += (-qb * gx_rps - qc * gy_rps - qd * gz_rps) * half_dt;
  q1 += (qa * gx_rps + qc * gz_rps - qd * gy_rps) * half_dt;
  q2 += (qa * gy_rps - qb * gz_rps + qd * gx_rps) * half_dt;
  q3 += (qa * gz_rps + qb * gy_rps - qc * gx_rps) * half_dt;

  s->q0 = q0;
  s->q1 = q1;
  s->q2 = q2;
  s->q3 = q3;
  quat_normalize(s);
}

// ------------------------ public APIs (MUST keep signatures) ------------------------
int alg_posture_init(alg_posture_config_t cfg)
{
  if (cfg.sample_us == 0) {
    cfg.sample_us = 2000; // default 500Hz
  }
  posture_config = cfg;

  memset(&state, 0, sizeof(state));
  state.q0 = 1.0f;
  state.valid = false;
  state.filter_valid = false;

  // keep position state too (safe default)
  memset(&pos_state, 0, sizeof(pos_state));
  pos_state.g_ref_mg = 1000.0f;

  return 0;
}

/**
 * Update posture at fixed sampling frequency.
 * Input units: accel mg, gyro dps, mag arbitrary.
 */
world_posture_t alg_posture_update(imu_data_t *data)
{
  if (!data) {
    return state.current;
  }

  float ax = data->ax;
  float ay = data->ay;
  float az = data->az;
  float gx = data->gx;
  float gy = data->gy;
  float gz = data->gz;
  float mx = data->mx;
  float my = data->my;
  float mz = data->mz;

  float dt = (float)posture_config.sample_us / 1000000.0f;
  if (!isfinite(dt) || dt <= 0.0f) {
    dt = 0.002f;
  }

  // 1st-order LPF for stability (cutoffs are conservative for motion analysis)
  const float acc_cutoff_hz = 10.0f;
  const float gyro_cutoff_hz = 20.0f;
  const float mag_cutoff_hz = 10.0f;

  const float tau_acc = 1.0f / (2.0f * (float)M_PI * acc_cutoff_hz);
  const float tau_gyro = 1.0f / (2.0f * (float)M_PI * gyro_cutoff_hz);
  const float tau_mag = 1.0f / (2.0f * (float)M_PI * mag_cutoff_hz);

  const float alpha_acc = dt / (tau_acc + dt);
  const float alpha_gyro = dt / (tau_gyro + dt);
  const float alpha_mag = dt / (tau_mag + dt);

  if (!state.filter_valid) {
    state.ax_f = ax;
    state.ay_f = ay;
    state.az_f = az;
    state.gx_f = gx;
    state.gy_f = gy;
    state.gz_f = gz;
    state.mx_f = mx;
    state.my_f = my;
    state.mz_f = mz;
    state.filter_valid = true;
  } else {
    if (is_finite3(ax, ay, az)) {
      state.ax_f = lpf_update(state.ax_f, ax, alpha_acc);
      state.ay_f = lpf_update(state.ay_f, ay, alpha_acc);
      state.az_f = lpf_update(state.az_f, az, alpha_acc);
    }
    if (is_finite3(gx, gy, gz)) {
      state.gx_f = lpf_update(state.gx_f, gx, alpha_gyro);
      state.gy_f = lpf_update(state.gy_f, gy, alpha_gyro);
      state.gz_f = lpf_update(state.gz_f, gz, alpha_gyro);
    }
    if (is_finite3(mx, my, mz)) {
      state.mx_f = lpf_update(state.mx_f, mx, alpha_mag);
      state.my_f = lpf_update(state.my_f, my, alpha_mag);
      state.mz_f = lpf_update(state.mz_f, mz, alpha_mag);
    }
  }

  ax = state.ax_f;
  ay = state.ay_f;
  az = state.az_f;
  gx = state.gx_f;
  gy = state.gy_f;
  gz = state.gz_f;
  mx = state.mx_f;
  my = state.my_f;
  mz = state.mz_f;

  // gyro norm in dps for stationary detect
  float gyro_norm_dps = norm3(gx, gy, gz);

  // convert gyro dps -> rad/s
  const float deg2rad = (float)M_PI / 180.0f;
  float gx_rps = gx * deg2rad;
  float gy_rps = gy * deg2rad;
  float gz_rps = gz * deg2rad;

  mahony_update(&state, gx_rps, gy_rps, gz_rps, ax, ay, az, mx, my, mz, dt);

  // gravity direction in body (unit)
  gravity_body_from_quat(&state, &state.gbx, &state.gby, &state.gbz);

  // linear accel in BODY (remove gravity using gravity direction)
  const float g_ref_mg = 1000.0f;           // 1g in mg
  const float mg_to_mps2 = 0.00980665f;
  float lin_bx = (ax - state.gbx * g_ref_mg) * mg_to_mps2;
  float lin_by = (ay - state.gby * g_ref_mg) * mg_to_mps2;
  float lin_bz = (az - state.gbz * g_ref_mg) * mg_to_mps2;

  // stationary detect: small gyro + small linear accel
  float lin_norm = norm3(lin_bx, lin_by, lin_bz);
  bool stationary = (gyro_norm_dps < 2.0f) && (lin_norm < 0.25f);

  // bias adaptation in BODY when stationary
  if (stationary) {
    const float bias_alpha = 0.01f;
    state.abx = lpf_update(state.abx, lin_bx, bias_alpha);
    state.aby = lpf_update(state.aby, lin_by, bias_alpha);
    state.abz = lpf_update(state.abz, lin_bz, bias_alpha);
  }

  // remove bias
  lin_bx -= state.abx;
  lin_by -= state.aby;
  lin_bz -= state.abz;

  state.current.ax = lin_bx;
  state.current.ay = lin_by;
  state.current.az = lin_bz;

  quat_to_euler_deg(&state, &state.current.yaw, &state.current.pitch, &state.current.roll);
  state.valid = true;

  return state.current;
}

world_position_t alg_position_update(const world_posture_t *posture,
                                     const imu_data_t *imu)
{
  world_position_t out = {
    .x = pos_state.x,
    .y = pos_state.y,
    .z = pos_state.z,
    .yaw = pos_state.last.yaw,
    .pitch = pos_state.last.pitch,
    .roll = pos_state.last.roll,
  };

  if (!posture || !imu) {
    return out;
  }

  world_posture_t p = *posture;
  out.yaw = p.yaw;
  out.pitch = p.pitch;
  out.roll = p.roll;

  if (!pos_state.valid) {
    pos_state.last = p;
    pos_state.valid = true;
    // reset filters
    pos_state.bx = pos_state.by = pos_state.bz = 0.0f;
    pos_state.ax_f = pos_state.ay_f = pos_state.az_f = 0.0f;
    pos_state.vx = pos_state.vy = pos_state.vz = 0.0f;
    pos_state.x = pos_state.y = pos_state.z = 0.0f;
    return out;
  }

#ifndef ALG_POSITION_SAMPLE_US
#define ALG_POSITION_SAMPLE_US 10000U
#endif

  // Fixed-rate integration. If you have real timestamps, replace this with measured dt.
  float dt = (float)ALG_POSITION_SAMPLE_US / 1000000.0f;
  if (!isfinite(dt) || dt <= 0.0f) {
    dt = 0.01f;
  }
  // clamp dt against occasional spikes
  if (dt < 0.0005f) dt = 0.0005f;
  if (dt > 0.05f)   dt = 0.05f;

  // raw accel in BODY (mg) - this is specific force (includes gravity)
  float ax_mg = imu->ax;
  float ay_mg = imu->ay;
  float az_mg = imu->az;
  if (!is_finite3(ax_mg, ay_mg, az_mg) || !state.valid) {
    pos_state.last = p;
    return out;
  }

  // ------------------------------------------------------------
  // Step 1) Remove gravity in BODY using gravity direction estimated by posture quaternion.
  //         (imu provides specific force; at rest |a| ≈ 1000 mg)
  // ------------------------------------------------------------
  float lin_bx_mg = ax_mg - state.gbx * pos_state.g_ref_mg;
  float lin_by_mg = ay_mg - state.gby * pos_state.g_ref_mg;
  float lin_bz_mg = az_mg - state.gbz * pos_state.g_ref_mg;

  // Convert BODY linear accel (still mg) -> m/s^2
// NOTE: Output requested is in DEVICE(BODY) XY, so we keep everything in BODY frame.
const float mg_to_mps2 = 0.00980665f;
float lin_bx = lin_bx_mg * mg_to_mps2;
float lin_by = lin_by_mg * mg_to_mps2;
float lin_bz = lin_bz_mg * mg_to_mps2;

  // Optional: clamp extreme spikes (helps with occasional glitches)
  {
    float n = norm3(lin_bx, lin_by, lin_bz);
    const float n_max = 30.0f; // ~3 g
    if (isfinite(n) && n > n_max && n > 0.0f) {
      float s = n_max / n;
      lin_bx *= s;
      lin_by *= s;
      lin_bz *= s;
    }
  }

  // ------------------------------------------------------------
  // Step 2) Stationary detect (cheap, but effective): posture delta + world linear accel norm
  // ------------------------------------------------------------
  float dy = angle_diff_deg(p.yaw, pos_state.last.yaw);
  float dp = angle_diff_deg(p.pitch, pos_state.last.pitch);
  float dr = angle_diff_deg(p.roll, pos_state.last.roll);
  float max_d = fmaxf(fmaxf(fabsf(dy), fabsf(dp)), fabsf(dr));
  float lin_norm = norm3(lin_bx, lin_by, lin_bz);

  const float stationary_angle_deg = 1.0f;
  const float stationary_lin_mps2 = 0.25f;
  bool stationary = (max_d < stationary_angle_deg) && (lin_norm < stationary_lin_mps2);

  // ------------------------------------------------------------
  // Step 3) Bias tracking in WORLD (key improvement):
  //   - A tiny constant error (bias or gravity projection) will integrate into a runaway line.
  //   - We track and subtract a slow-varying "DC" component from a_lin_world.
  //   - When stationary, adapt faster and also do ZUPT.
  // ------------------------------------------------------------
  float tau_bias_s = stationary ? 0.35f : 2.0f; // stationary: fast; moving: slow
  if (tau_bias_s < 0.05f) tau_bias_s = 0.05f;
  float alpha_bias = dt / (tau_bias_s + dt);

  pos_state.bx = lpf_update(pos_state.bx, lin_bx, alpha_bias);
  pos_state.by = lpf_update(pos_state.by, lin_by, alpha_bias);
  pos_state.bz = lpf_update(pos_state.bz, lin_bz, alpha_bias);

  // Subtract bias (high-pass effect)
  lin_bx -= pos_state.bx;
  lin_by -= pos_state.by;
  lin_bz -= pos_state.bz;

  // ------------------------------------------------------------
  // Step 4) Low-pass linear accel (makes trajectory "presentable")
  // ------------------------------------------------------------
  const float fc_acc_hz = 8.0f;
  float tau_acc = 1.0f / (2.0f * (float)M_PI * fc_acc_hz);
  float alpha_acc = dt / (tau_acc + dt);

  pos_state.ax_f = lpf_update(pos_state.ax_f, lin_bx, alpha_acc);
  pos_state.ay_f = lpf_update(pos_state.ay_f, lin_by, alpha_acc);
  pos_state.az_f = lpf_update(pos_state.az_f, lin_bz, alpha_acc);

  // ------------------------------------------------------------
  // Step 5) ZUPT + gravity magnitude update when stationary
  // ------------------------------------------------------------
  if (stationary) {
    pos_state.vx = 0.0f;
    pos_state.vy = 0.0f;
    pos_state.vz = 0.0f;

    // update gravity magnitude reference (mg) slowly using raw accel magnitude
    const float g_alpha = 0.02f;
    float acc_norm_mg = norm3(ax_mg, ay_mg, az_mg);
    if (isfinite(acc_norm_mg) && acc_norm_mg > 100.0f) {
      pos_state.g_ref_mg = lpf_update(pos_state.g_ref_mg, acc_norm_mg, g_alpha);
    }

    // also pull accel filter toward 0 to avoid a "kick" when leaving stationary
    pos_state.ax_f *= 0.5f;
    pos_state.ay_f *= 0.5f;
    pos_state.az_f *= 0.5f;
  }

  // ------------------------------------------------------------
  // Step 6) Integrate velocity/position
  // ------------------------------------------------------------
  pos_state.vx += pos_state.ax_f * dt;
  pos_state.vy += pos_state.ay_f * dt;
  // ignore device Z displacement
  pos_state.vz = 0.0f;
// velocity leak to keep trajectory bounded
  const float vel_leak = 0.08f; // stronger default to avoid runaway
  float k = 1.0f - vel_leak * dt;
  if (k < 0.0f) k = 0.0f;
  if (k > 1.0f) k = 1.0f;
  pos_state.vx *= k;
  pos_state.vy *= k;
  pos_state.vz *= k;

  pos_state.x += pos_state.vx * dt;
  pos_state.y += pos_state.vy * dt;
  pos_state.z = 0.0f;
pos_state.last = p;

  // Output requirement:
//   1) Only need 2D trajectory in DEVICE(BODY) coordinates (x/y).
//   2) Ignore motion along device Z axis: set output z = 0.
// We keep integrating in WORLD for stability, then convert the integrated
// position into BODY frame at the current posture.
out.x = pos_state.x;
  out.y = pos_state.y;
  out.z = 0.0f;
  return out;
}

bool alg_posture_is_yaw_balanced(void)
{
  if (!state.valid) {
    return false;
  }
  if (posture_config.balance_yaw_thresh < 0.0f) {
    return true;
  }
  float dy = angle_diff_deg(state.current.yaw, posture_config.balance_yaw);
  return fabsf(dy) <= posture_config.balance_yaw_thresh;
}

bool alg_posture_is_pitch_balanced(void)
{
  if (!state.valid) {
    return false;
  }
  if (posture_config.balance_pitch_thresh < 0.0f) {
    return true;
  }
  float dp = angle_diff_deg(state.current.pitch, posture_config.balance_pitch);
  return fabsf(dp) <= posture_config.balance_pitch_thresh;
}

bool alg_posture_is_roll_balanced(void)
{
  if (!state.valid) {
    return false;
  }
  if (posture_config.balance_roll_thresh < 0.0f) {
    return true;
  }
  float dr = angle_diff_deg(state.current.roll, posture_config.balance_roll);
  return fabsf(dr) <= posture_config.balance_roll_thresh;
}

int alg_posture_update_threshold(uint8_t axis, float threshold_deg)
{
  switch (axis) {
    case ALG_POSTURE_AXIS_YAW:
      posture_config.balance_yaw_thresh = threshold_deg;
      break;
    case ALG_POSTURE_AXIS_PITCH:
      posture_config.balance_pitch_thresh = threshold_deg;
      break;
    case ALG_POSTURE_AXIS_ROLL:
      posture_config.balance_roll_thresh = threshold_deg;
      break;
    default:
      return -EINVAL;
  }
  return 0;
}

#endif
```

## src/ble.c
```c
#include "inc/ble.h"

#include <zephyr/sys/util.h>
#include <zephyr/settings/settings.h>
#include <zephyr/bluetooth/bluetooth.h>
#include <zephyr/bluetooth/gatt.h>

#include "inc/ble_conn.h"
#include "inc/ble_aaaa.h"

void mtu_updated(struct bt_conn *conn, uint16_t tx, uint16_t rx)
{
	printk("Updated MTU: TX: %d RX: %d bytes\n", tx, rx);
}
static struct bt_gatt_cb gatt_callbacks = {.att_mtu_updated = mtu_updated};

int ble_init()
{
  int err = 0;
  
  // Bluetooth
  err = bt_enable(NULL);
  if (err)
  {
    // LOG_ERR("Bluetooth init failed (err %d)", err);
    // return -1;
  }
  bt_gatt_cb_register(&gatt_callbacks);
  // // // LOG_INF("Bluetooth init success.");
  // // if (IS_ENABLED(CONFIG_BT_SETTINGS))
  // // {
  // //   settings_load();
  // //   // LOG_INF("Settings init success.");
  // // }

  err = ble_aaaa_init();
  if (err) { return err; }
  
  err = ble_adv_init();
  if (err) { return err; }
  
  err = ble_adv_start();
  if (err) { return err; }

  return 0;
}

int ble_uninit()
{
  ble_adv_stop();
  bt_disable();
  return 0;
}
```
